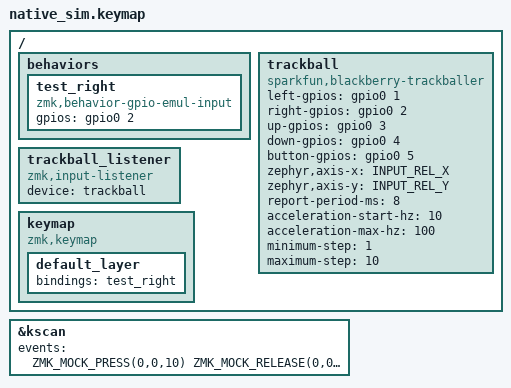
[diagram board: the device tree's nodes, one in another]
#include <zephyr/dt-bindings/gpio/gpio.h>
#include <zephyr/dt-bindings/input/input-event-codes.h>

#include <behaviors.dtsi>
#include <dt-bindings/zmk/kscan_mock.h>

/ {
    behaviors {
        test_right: test_right {
            compatible = "zmk,behavior-gpio-emul-input";
            #binding-cells = <0>;
            gpios = <&gpio0 2 GPIO_ACTIVE_HIGH>;
        };
    };

    trackball: trackball {
        compatible = "sparkfun,blackberry-trackballer";
        left-gpios = <&gpio0 1 GPIO_ACTIVE_HIGH>;
        right-gpios = <&gpio0 2 GPIO_ACTIVE_HIGH>;
        up-gpios = <&gpio0 3 GPIO_ACTIVE_HIGH>;
        down-gpios = <&gpio0 4 GPIO_ACTIVE_HIGH>;
        button-gpios = <&gpio0 5 GPIO_ACTIVE_HIGH>;
        zephyr,axis-x = <INPUT_REL_X>;
        zephyr,axis-y = <INPUT_REL_Y>;
        report-period-ms = <8>;
        acceleration-start-hz = <10>;
        acceleration-max-hz = <100>;
        minimum-step = <1>;
        maximum-step = <10>;
    };

    trackball_listener: trackball_listener {
        compatible = "zmk,input-listener";
        device = <&trackball>;
    };

    keymap {
        compatible = "zmk,keymap";

        default_layer {
            bindings = <&test_right>;
        };
    };
};

&kscan {
    events = <
        /* Default exponent 2: first pulse, 10, 40, about 71, 100, then 5 Hz. */
        ZMK_MOCK_PRESS(0,0,10)
        ZMK_MOCK_RELEASE(0,0,90)
        ZMK_MOCK_PRESS(0,0,10)
        ZMK_MOCK_RELEASE(0,0,15)
        ZMK_MOCK_PRESS(0,0,5)
        ZMK_MOCK_RELEASE(0,0,9)
        ZMK_MOCK_PRESS(0,0,5)
        ZMK_MOCK_RELEASE(0,0,5)
        ZMK_MOCK_PRESS(0,0,10)
        ZMK_MOCK_RELEASE(0,0,190)
        ZMK_MOCK_PRESS(0,0,10)
        ZMK_MOCK_RELEASE(0,0,20)
    >;
};
